# GD32H77x_78x register map
File version: 1.0
CPU: CM7 r1p2, little endian, MPU, FPU, 4 interrupt priority bits
Registers are 32-bit, read-write, reset 0x0 unless marked. A register's access mark holds for its fields unless they carry their own. Offsets are from the block's base; [hi:lo] are bit positions; 'fields as' and 'values as' point back to an identical list.

## DSI — DSI host controller
Base 0x52003000
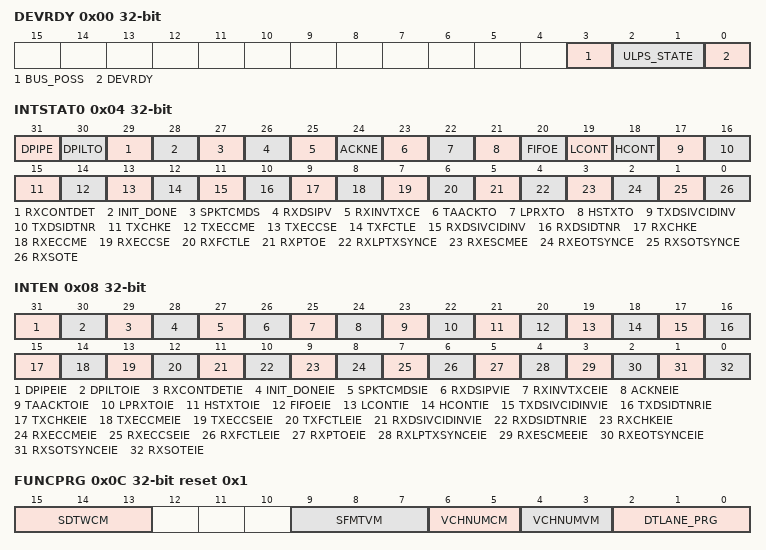
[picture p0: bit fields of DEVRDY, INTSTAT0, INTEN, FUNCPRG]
0x00 DEVRDY — DSI Host device ready register
  [3] BUS_POSS — Display bus possession
  [2:1] ULPS_STATE — Inform entire DSI host to enter ultra low power state(ULPS).
  [0] DEVRDY — Device ready. Set by the processor to inform that device is ready for transmission.
0x04 INTSTAT0 — DSI Host interrupt status register0
  [31] DPIPE — DPI program error
  [30] DPILTO — DPI line timeout
  [29] RXCONTDET — Rx Contention Detected.
  [28] INIT_DONE — DSI initialisation is done.
  [27] SPKTCMDS — Special packet command sent.
  [26] RXDSIPV — Rx DSI protocol violation.
  [25] RXINVTXCE — Rx Invalid transmission count error.
  [24] ACKNE — ACK with No error
  [23] TAACKTO — Turn around ack timeout
  [22] LPRXTO — LP Rx timeout
  [21] HSTXTO — HS Tx timeout
  [20] FIFOE — FIFO empty.
  [19] LCONT — Low contention
  [18] HCONT — High contention.
  [17] TXDSIVCIDINV — Tx DSI virtual channel ID invalid
  [16] TXDSIDTNR — Tx DSI data type not recognized
  [15] TXCHKE — Tx checksum(CRC) error
  [14] TXECCME — Tx ECC multibit error
  [13] TXECCSE — Tx ECC single bit error
  [12] TXFCTLE — Tx False Control Error
  [11] RXDSIVCIDINV — Rx DSI virtual channel ID invalid
  [10] RXDSIDTNR — Rx DSI data type not recognized
  [9] RXCHKE — Rx checksum error
  [8] RXECCME — Rx ECC multibit error
  [7] RXECCSE — Rx ECC single bit error
  [6] RXFCTLE — RxFalse Control Error.
  [5] RXPTOE — Rx Peripheral timeout Error.
  [4] RXLPTXSYNCE — Rx LP tx sync error.
  [3] RXESCMEE — Rx Escape Mode Entry Error.
  [2] RXEOTSYNCE — Rx Eot sync Error.
  [1] RXSOTSYNCE — Rx Sot Sync Error.
  [0] RXSOTE — Rx Sot Error.
0x08 INTEN — DSI Host interrupt enable register
  [31] DPIPEIE — DPI program error interrupt enable.
  [30] DPILTOIE — Enable DPI line timeout interrupt enable.
  [29] RXCONTDETIE — Rx Contention Detected interrupt enable.
  [28] INIT_DONEIE — DSI initialisation is done interrupt enable.
  [27] SPKTCMDSIE — Special packet command sent interrupt enable.
  [26] RXDSIPVIE — Rx DSI protocol violation interrupt enable.
  [25] RXINVTXCEIE — Rx Invalid transmission count error interrupt enable.
  [24] ACKNEIE — ACK with No error interrupt enable.
  [23] TAACKTOIE — Turn around ack timeout interrupt enable.
  [22] LPRXTOIE — LP Rx timeout interrupt enable.
  [21] HSTXTOIE — HS Tx timeout interrupt enable.
  [20] FIFOEIE — FIFO empty interrupt enable.
  [19] LCONTIE — Low contention interrupt enable.
  [18] HCONTIE — High contention interrupt enable.
  [17] TXDSIVCIDINVIE — Tx DSI virtual channel ID invalid interrupt enable.
  [16] TXDSIDTNRIE — Tx DSI data type not recognized interrupt enable.
  [15] TXCHKEIE — Tx checksum(CRC) error interrupt enable.
  [14] TXECCMEIE — Tx ECC multibit error interrupt enable.
  [13] TXECCSEIE — Tx ECC single bit error interrupt enable.
  [12] TXFCTLEIE — Tx False Control Error interrupt enable.
  [11] RXDSIVCIDINVIE — Rx DSI virtual channel ID invalid interrupt enable.
  [10] RXDSIDTNRIE — Rx DSI data type not recognized interrupt enable.
  [9] RXCHKEIE — Rx checksum error interrupt enable.
  [8] RXECCMEIE — Rx ECC multibit error interrupt enable.
  [7] RXECCSEIE — Rx ECC single bit error interrupt enable.
  [6] RXFCTLEIE — RxFalse Control Error interrupt enable.
  [5] RXPTOEIE — Rx Peripheral timeout Error interrupt enable.
  [4] RXLPTXSYNCEIE — Rx LP tx sync error interrupt enable.
  [3] RXESCMEEIE — Rx Escape Mode Entry Error interrupt enable.
  [2] RXEOTSYNCEIE — Rx Eot sync Error interrupt enable.
  [1] RXSOTSYNCEIE — Rx Sot Sync Error interrupt enable.
  [0] RXSOTEIE — Rx Sot Error interrupt enable.
0x0C FUNCPRG reset 0x1 — DSI Host function program register
  [15:13] SDTWCM — Supported data width in command mode.
  [9:7] SFMTVM — Supported colour format for video mode.
  [6:5] VCHNUMCM — Virtual channel number for command mode.
  [4:3] VCHNUMVM — Virtual channel number for video mode.
  [2:0] DTLANE_PRG — Number of data lanes.
0x10 HSTXTO reset 0xFFFF — DSI Host high speed transmission timeout register
  [23:0] HSTXTOCNT — High speed transmission timeout counter.
0x14 LPRXTO reset 0xFFFF — DSI Host low power reception timeout register
  [23:0] LPRXTOCNT — Low power reception timeout counter.
0x18 TATO reset 0x17 — DSI Host turn around timeout register
  [5:0] TATO — Turn around timeout.
0x1C DEVRSTTM reset 0xFF — DSI Host device reset timer register
  [15:0] DEVRTSTTM — Device reset timer.
0x20 DPIRES — DSI Host DPI resolution register
  [31:0] DPIRES — DPI resolution
0x24 DCSWC — DSI Host DCS word count register
  [15:0] DCSWC — DCS/Generic word count values need to be written before DCS or Generic long write.
0x28 HSACFG — DSI Host horizontal sync active count configuration register
  [15:0] HSACNT — Horizontal sync active count value
0x2C HBPCFG — DSI Host horizontal back porch count configuration register
  [15:0] HBPCNT — Horizontal back porch count value
0x30 HFPCFG — DSI Host horizontal front porch count configuration register
  [15:0] HFPCNT — Horizontal front porch count value
0x34 HACFG — DSI Host horizontal active area count configuration register
  [15:0] HACNT — Horizontal active area count, that is the time for active Horizontal Address.
0x38 VSACFG — DSI Host vertical sync active count configuration register
  [15:0] VSACNT — Vertical sync active count value.
0x3C VBPCFG — DSI Host vertical back porch count configuration register
  [15:0] VBPCNT — Vertical back porch count value.
0x40 VFPCFG — DSI Host vertical front porch count configuration register
  [15:0] VFPCNT — Vertical front porch count value.
0x44 DLCFG — DSI Host data lane high low switch count configuration register
  [15:0] DLCFG — Switch count of HS to LP or LP to HS for Data lane.
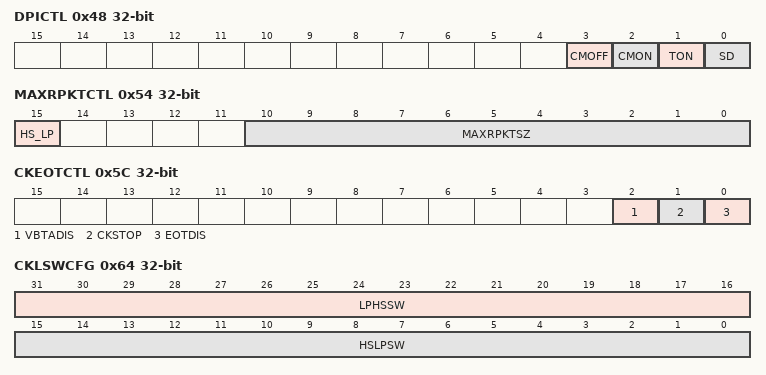
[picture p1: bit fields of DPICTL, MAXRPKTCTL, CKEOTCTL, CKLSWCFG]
0x48 DPICTL — DSI Host DPI control register
  [3] CMOFF — Color Mode OFF(0x08) command is packetised for the DPI virtual channel.
  [2] CMON — Color Mode ON(0x04) command is packetised for the DPI virtual channel.
  [1] TON — Turn ON (0x02) command is packetised for the DPI virtual channel.
  [0] SD — Shut down(0x01) command is packetised for the DPI virtual channel.
0x4C DPHY_PLLLK reset 0x7D0 — DSI Host Dphy PLL lock count register
  [15:0] PLLCNTVAL — PLL counter value in terms of low power clock.
0x50 INITCFG reset 0x7D0 — DSI Host initialization count configuration register
  [15:0] INITCNT — Counter value
0x54 MAXRPKTCTL — DSI Host maximum return packet control registe
  [15] HS_LP — Indicates the data transfer type
  [10:0] MAXRPKTSZ — Maximum return packet size in bytes.
0x58 VMFMT — DSI Host Video mode format register
  [1:0] VMFMT — Video mode format
0x5C CKEOTCTL — DSI Host clock EOT control register
  [2] VBTADIS — Disable video BTA
  [1] CKSTOP — Enable clock stopping feature.
  [0] EOTDIS — Disable EOT packet(EoTp) transmission
0x60 PLCTL — DSI Host polarity control register
  [3:0] PL — Polarity
0x64 CKLSWCFG — DSI Host clock lane switching configuration register
  [31:16] LPHSSW — LP to HS switching counter for clock Lane
  [15:0] HSLPSW — HS to LP switching counter for clock Lane
0x68 LPBCLKCFG reset 0x1 — DSI Host low power byte clock configuration register
  [15:0] LPBYTECLK — LP clock equivalence in terms of byte clock.
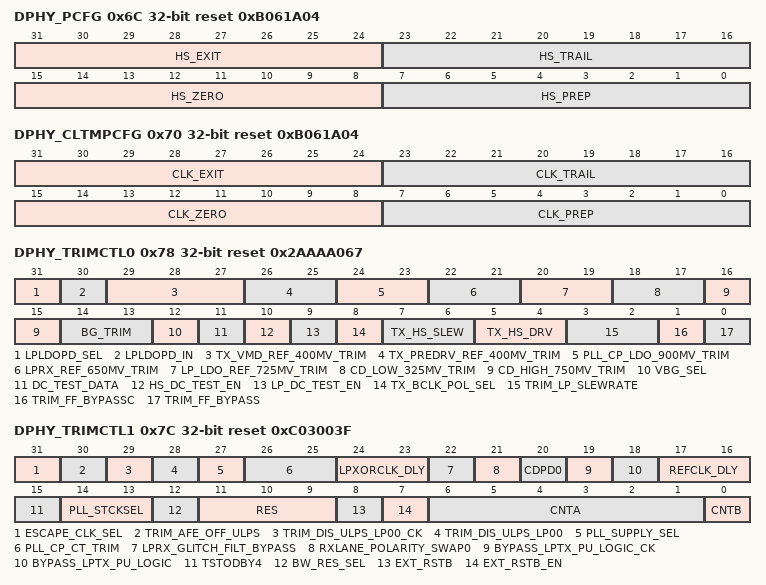
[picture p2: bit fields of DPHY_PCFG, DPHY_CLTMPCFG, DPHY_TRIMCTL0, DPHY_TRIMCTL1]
0x6C DPHY_PCFG reset 0xB061A04 — DSI Host Dphy parameter configuration register
  [31:24] HS_EXIT — HS exit time(THS-EXIT).
  [23:16] HS_TRAIL — HS trail time(THS-TRAIL).
  [15:8] HS_ZERO — HS drive zero time(THS-ZERO).
  [7:0] HS_PREP — HS preparation time(THS-PREPARE).
0x70 DPHY_CLTMPCFG reset 0xB061A04 — DSI Host Dphy clock lane timing parameter configuration register
  [31:24] CLK_EXIT — CLK exit time(TCLK-EXIT).
  [23:16] CLK_TRAIL — CLK trail time(TCLK-TRAIL).
  [15:8] CLK_ZERO — CLK drive zero time(TCLK-ZERO).
  [7:0] CLK_PREP — CLK preparation time(TCLK-PREPARE).
0x74 DPHY_RSTENDFE — DSI Host Dphy reset enable to DFE register
  [0] RSTENDFE — Reset (enable) to the Digital Front End(DFE)
0x78 DPHY_TRIMCTL0 reset 0x2AAAA067 — DSI Host Dphy trim control register 0
  [31] LPLDOPD_SEL — LP LDO power down selection
  [30] LPLDOPD_IN — External LP LDO power down
  [29:27] TX_VMD_REF_400MV_TRIM — Adjust HS TX common mode voltage
  [26:25] TX_PREDRV_REF_400MV_TRIM — Adjust HS TX pre-driver LDO reference voltage
  [24:23] PLL_CP_LDO_900MV_TRIM — Adjust PLL CP LDO reference voltage
  [22:21] LPRX_REF_650MV_TRIM — Adjust LP RX reference voltage
  [20:19] LP_LDO_REF_725MV_TRIM — Adjust LP LDO reference voltage
  [18:17] CD_LOW_325MV_TRIM — Adjust CD reference Low voltage
  [16:15] CD_HIGH_750MV_TRIM — Adjust CD reference High voltage
  [14:13] BG_TRIM — Adjust bandgap reference voltage
  [12] VBG_SEL — Select the PVT independent Bandgap voltage
  [11] DC_TEST_DATA — LP or HS data to transmit out when anyone of the DC test is enabled
  [10] HS_DC_TEST_EN — Enable HS transmitter DC test
  [9] LP_DC_TEST_EN — Enable LP transmitter DC test
  [8] TX_BCLK_POL_SEL — Select the TX byte clock polarity.
  [7:6] TX_HS_SLEW — Adjust the HS transmit signal slew rate
  [5:4] TX_HS_DRV — Adjust the HS driver impedance
  [3:2] TRIM_LP_SLEWRATE — Adjust the LP transmit signal slew rate
  [1] TRIM_FF_BYPASSC — Used to bypass the LPTX signals sampling done by the reference clock
  [0] TRIM_FF_BYPASS — Used to bypass the LPTX signals sampling done by the reference clock
0x7C DPHY_TRIMCTL1 reset 0xC03003F — DSI Host Dphy trim control register 1
  [31] ESCAPE_CLK_SEL — It is used to select the reference clock
  [30] TRIM_AFE_OFF_ULPS — Enable to power off all AFE blocks in ULPS
  [29] TRIM_DIS_ULPS_LP00_CK — Disable weak pull-down resistor added in mipi clock lane
  [28] TRIM_DIS_ULPS_LP00 — Disable weak pull-down resistor added in mipi data lanes
  [27] PLL_SUPPLY_SEL — PLL CP supply voltage selection
  [26:25] PLL_CP_CT_TRIM — Programmable PLL charge pump current
  [24:23] LPXORCLK_DLY — Programmable delay in LP XOR clock
  [22] LPRX_GLITCH_FILT_BYPASS — LPXOR clock glitch filter bypass enable
  [21] RXLANE_POLARITY_SWAP0 — Control to swap the polarity of the RX output
  [20] CDPD0 — Contention detection block power down signal
  [19] BYPASS_LPTX_PU_LOGIC_CK — LP11 initialization bypass signal for clock lane
  [18] BYPASS_LPTX_PU_LOGIC — LP11 initialization bypass signal for data lanes
  [17:16] REFCLK_DLY — Programmable escape clock delay in AFE to capture the LP data driven by the DFE
  [15] TSTODBY4 — Control to select Clock Divide by 4 or Clock Divide by 8 as output.
  [14:13] PLL_STCKSEL — Control to select a clock from PLL to test
  [12] BW_RES_SEL — PLL LPF resistor selection
  [11:9] RES — LPF resistor selection
  [8] EXT_RSTB — External active-low reset
  [7] EXT_RSTB_EN — Enable external active-low reset
  [6:1] CNTA — PLL Divider ratio used in counter.
  [0] CNTB — Reference CNTA[5:0]
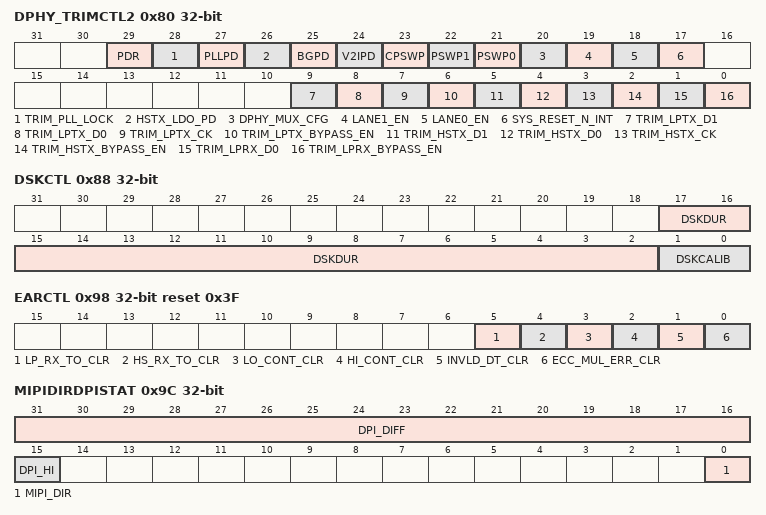
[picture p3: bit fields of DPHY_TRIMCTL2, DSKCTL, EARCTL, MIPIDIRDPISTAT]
0x80 DPHY_TRIMCTL2 — DSI Host Dphy trim control register 2
  [29] PDR — Power down control
  [28] TRIM_PLL_LOCK — Force PLL lock detect high
  [27] PLLPD — Force PLL circuits power down if PDR is set 1
  [26] HSTX_LDO_PD — Force high speed driver LDO circuits power down
  [25] BGPD — Force bandgap circuits power down if PDR is set 1
  [24] V2IPD — Force bias circuits power down if PDR is set 1
  [23] CPSWP — Clock lane polarity swap enable
  [22] PSWP1 — Data lane 1 polarity swap enable
  [21] PSWP0 — Data lane 0 polarity swap enable
  [20] DPHY_MUX_CFG — Lane swap configuration bit
  [19] LANE1_EN — lane enable control for lane1
  [18] LANE0_EN — lane enable control for lane0
  [17] SYS_RESET_N_INT — Optional system reset signal
  [9] TRIM_LPTX_D1 — Control to overwrite LP TX data of data lane1
  [8] TRIM_LPTX_D0 — Control to overwrite LP TX data of data lane0
  [7] TRIM_LPTX_CK — Control to overwrite LP TX data of clock lane
  [6] TRIM_LPTX_BYPASS_EN — Control to overwrite LP TX enable
  [5] TRIM_HSTX_D1 — Control to overwrite HS TX data of data lane1
  [4] TRIM_HSTX_D0 — Control to overwrite HS TX data of data lane0
  [3] TRIM_HSTX_CK — Control to overwrite HS TX data of clock lane
  [2] TRIM_HSTX_BYPASS_EN — Control to overwrite HS TX enable
  [1] TRIM_LPRX_D0 — Control to overwrite LP RX data
  [0] TRIM_LPRX_BYPASS_EN — Control to overwrite LP RX enable
0x88 DSKCTL — DSI Host deskew control register
  [17:2] DSKDUR — deskew duration
  [1:0] DSKCALIB — deskew calibration
0x8C DSKTM — DSI Host periodic deskew timer registe
  [15:0] DSKTM — Periodic deskew timer
0x90 DSKSTAT ro — DSI Host deskew status register
  [0] DSKIP — Deskew calibration is in progress.
0x98 EARCTL reset 0x3F — DSI Host error auto recovery control register
  [5] LP_RX_TO_CLR — lp_rx_timeout_clr error recovery action is taken immediately by DSI TX
  [4] HS_RX_TO_CLR — Hs_rx_timeout_clr error recovery action is taken immediately by DSI TX
  [3] LO_CONT_CLR — lo_cont_clr error recovery action is taken immediately by DSI TX
  [2] HI_CONT_CLR — Hi_cont_clr error recovery action is taken immediately by DSI TX
  [1] INVLD_DT_CLR — Invld_dt_clr error recovery action is taken immediately by DSI TX
  [0] ECC_MUL_ERR_CLR — Ecc_mul_err_clr error recovery action is taken immediately by DSI TX
0x9C MIPIDIRDPISTAT ro — DSI Host MIPI direction and DPI status register
  [31:16] DPI_DIFF — The difference in one line time between DPI and DSI.
  [15] DPI_HI — DPI line time is greater or DSI line time is greater.
  [0] MIPI_DIR — MIPI BUS direction
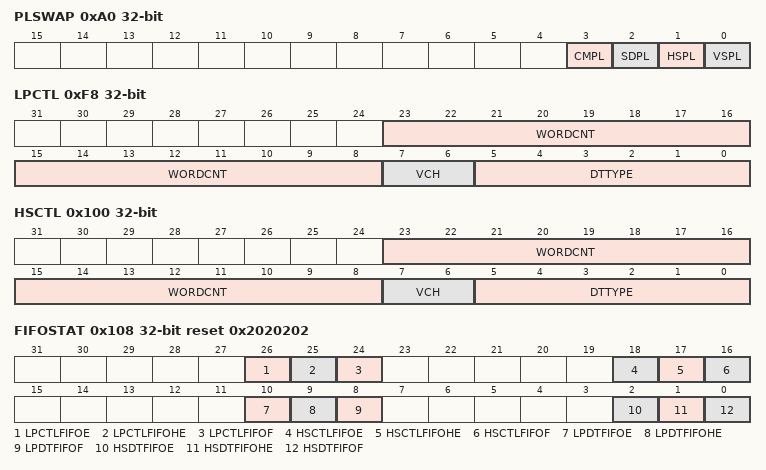
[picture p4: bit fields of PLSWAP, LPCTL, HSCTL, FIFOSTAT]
0xA0 PLSWAP — DSI Host Polarity Swap register
  [3] CMPL — Color mode polarity
  [2] SDPL — Shutdown polarity
  [1] HSPL — Hsync polarity
  [0] VSPL — Vsync polarity
0xA4 FMCTL — DSI Host frequency mode control register
  [0] FREQMOD — frequency mode
0xB0 TXDTWCFG — DSI Host Tx data width configuration register
  [7:0] TXDTWIDTH — Tx data width hs
0xF8 LPCTL — DSI Host LP control register
  [23:8] WORDCNT — Word count
  [7:6] VCH — Virtual channel
  [5:0] DTTYPE — Data type
0xFC LPDATA — DSI Host LP data register
  [31:0] LPDATA — Data Used for Generic/ DCS data transfers in low power mode.
0x100 HSCTL — DSI Host HS control register
  fields as LPCTL
0x104 HSDATA — DSI Host HS data register
  [31:0] HSDATA — Data Used for Generic/ DCS data transfers in high-speed mode.
0x108 FIFOSTAT ro reset 0x2020202 — DSI Host FIFO status register
  [26] LPCTLFIFOE — LP Generic/DCS control FIFO empty
  [25] LPCTLFIFOHE — LP Generic/DCS control FIFO half empty
  [24] LPCTLFIFOF — LP Generic/DCS control FIFO full
  [18] HSCTLFIFOE — HS Generic/DCS control FIFO empty
  [17] HSCTLFIFOHE — HS Generic/DCS control FIFO half empty
  [16] HSCTLFIFOF — HS Generic/DCS control FIFO full
  [10] LPDTFIFOE — LP Generic/DCS data FIFO empty
  [9] LPDTFIFOHE — LP Generic/DCS data FIFO half empty
  [8] LPDTFIFOF — LP Generic/DCS data FIFO full
  [2] HSDTFIFOE — HS Generic/DCS data FIFO empty
  [1] HSDTFIFOHE — HS Generic/DCS data FIFO half empty
  [0] HSDTFIFOF — HS Generic/DCS data FIFO full
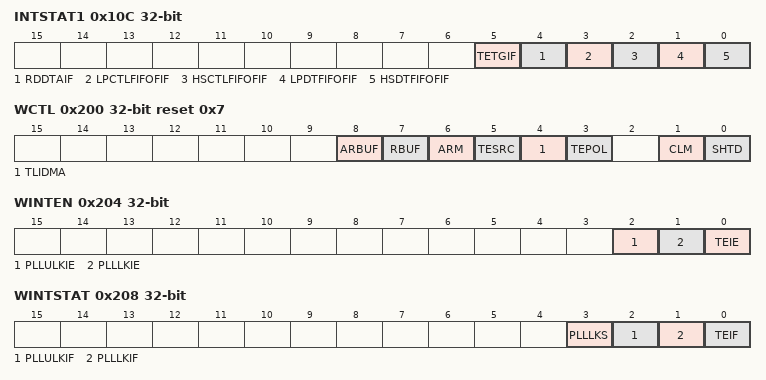
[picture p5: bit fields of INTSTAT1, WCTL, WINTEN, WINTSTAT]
0x10C INTSTAT1 — DSI Host interrupt status register1
  [5] TETGIF — Tearing effect(TE) trigger message received
  [4] RDDTAIF — LP Generic/DCS read data available.
  [3] LPCTLFIFOFIF — LP Generic/DCS control FIFO full
  [2] HSCTLFIFOFIF — HS Generic/DCS control FIFO full
  [1] LPDTFIFOFIF — LP Generic/DCS data FIFO full
  [0] HSDTFIFOFIF — HS Generic/DCS data FIFO full
0x200 WCTL access per field reset 0x7 — DSI Wrapper control register
  [8] ARBUF rw — Hardware auto refresh cmd fifo buffer enable
  [7] RBUF wo — Refresh cmd fifo buffer
  [6] ARM rw — Automatic refresh mode
  [5] TESRC rw — Tearing effect (TE) source
  [4] TLIDMA rw — TLI DMA mode
  [3] TEPOL rw — TE pin polarity
  [1] CLM rw — Color mode
  [0] SHTD rw — Shutdown
0x204 WINTEN — DSI Wrapper interrupt enable register
  [2] PLLULKIE — PLL unlock interrupt enable
  [1] PLLLKIE — PLL lock interrupt enable
  [0] TEIE — Tearing effect interrupt enable
0x208 WINTSTAT access per field — DSI Wrapper interrupt and status register
  [3] PLLLKS ro — PLL lock status
  [2] PLLULKIF rw — PLL unlock interrupt flag
  [1] PLLLKIF rw — PLL lock interrupt flag
  [0] TEIF rw — Tearing effect interrupt flag
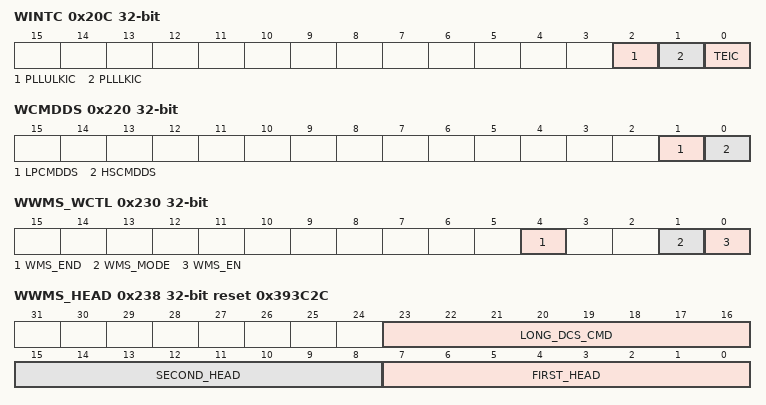
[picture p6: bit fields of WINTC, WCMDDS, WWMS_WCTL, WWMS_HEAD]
0x20C WINTC wo — DSI Wrapper interrupt flag clear register
  [2] PLLULKIC — PLL unlock interrupt flag clear
  [1] PLLLKIC — PLL lock interrupt flag clear
  [0] TEIC — Tearing effect interrupt flag clear
0x210 WRGBDF — DSI Wrapper RGB data format register
  [2:0] TLI_DF — TLI data format select
0x220 WCMDDS — DSI Wrapper command mode data source register
  [1] LPCMDDS — Command mode low power fifo write data source
  [0] HSCMDDS — Command mode high speed fifo write data source
0x224 WDMARCTL — DSI Wrapper DMA request control register
  [6:4] DMASRC — DMA request source select
0x230 WWMS_WCTL — DSI Wrapper WMS write control register
  [4] WMS_END — Write memory split packet end flag
  [1] WMS_MODE — WMS function used for different modes
  [0] WMS_EN — Write memory split packet enable
0x234 WWMS_INTMSK — DSI Wrapper WMS interrupt mask register
  [4] WMS_ENDMSK — WMS_END flag interrupt signal mask
0x238 WWMS_HEAD reset 0x393C2C — DSI Wrapper WMS header message register
  [23:16] LONG_DCS_CMD — Long packet DCS command
  [15:8] SECOND_HEAD — Secondary split packet head message
  [7:0] FIRST_HEAD — First split packet head message
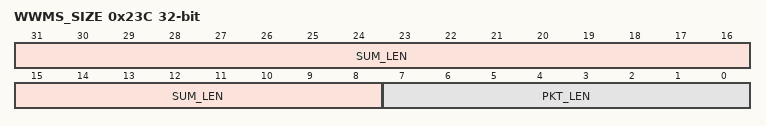
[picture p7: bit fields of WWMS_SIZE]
0x23C WWMS_SIZE — DSI Wrapper WMS size control register
  [31:8] SUM_LEN — The total number of words to be transferred by a single DMA trigger, which can generally be set to the data size of one frame.
  [7:0] PKT_LEN — Divide the DMA into the length of each packet, in the number of words.
0x240 WWMS_STAT0 ro — DSI Wrapper WMS status register 0
  [15:0] PKT_NUM — The number of packets into which the current DMA transfer has been split.
0x244 WWMS_STAT1 ro — DSI Wrapper WMS status register 1
  [23:0] SUM_CNT — The total amount of data that has been transferred for the current DMA operation.
